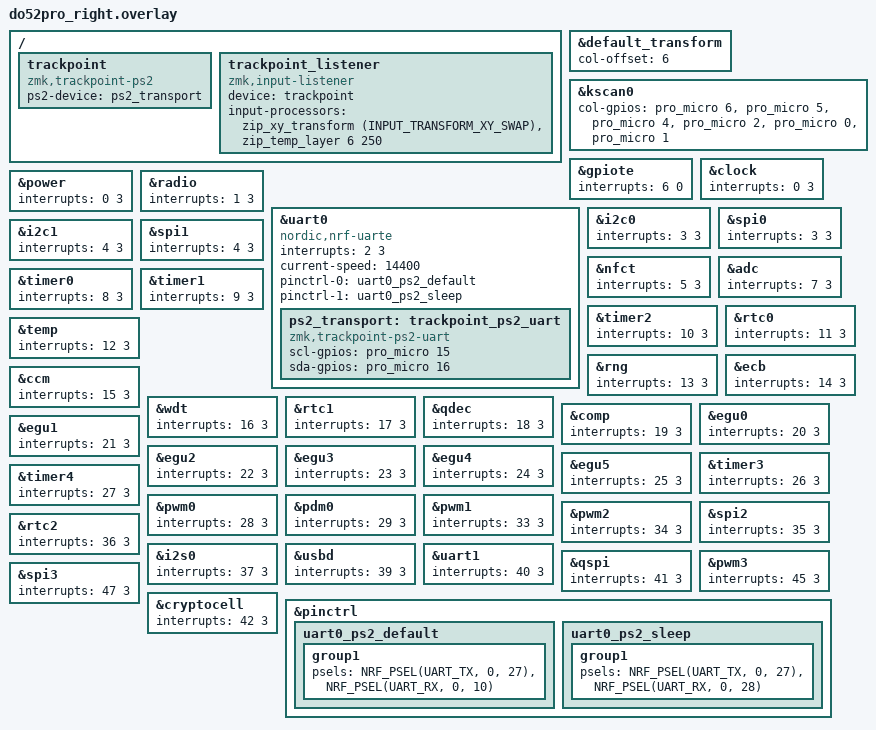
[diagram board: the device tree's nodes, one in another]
#include "do52pro.dtsi"

#include <input/processors.dtsi>
#include <dt-bindings/zmk/input_transform.h>

&default_transform {
    col-offset = <6>;
};

&kscan0 {
    col-gpios
        = <&pro_micro 6 GPIO_ACTIVE_HIGH>
        , <&pro_micro 5 GPIO_ACTIVE_HIGH>
        , <&pro_micro 4 GPIO_ACTIVE_HIGH>
        , <&pro_micro 2 GPIO_ACTIVE_HIGH>
        , <&pro_micro 0 GPIO_ACTIVE_HIGH>
        , <&pro_micro 1 GPIO_ACTIVE_HIGH>
        ;
};

// PS/2 TrackPoint via UART transport
// Pins: SCL=D15 (P1.13), SDA=D16 (P0.10)

// Interrupt priority overrides: the PS/2 clock runs at 10-16.7kHz, so its
// GPIO interrupt must preempt everything, including the BLE radio.
&gpiote { interrupts = < 6 0 >; };
&clock { interrupts = < 0 3 >; };
&power { interrupts = < 0 3 >; };
&radio { interrupts = < 1 3 >; };
&uart0 { interrupts = < 2 3 >; };
&i2c0 { interrupts = < 3 3 >; };
&spi0 { interrupts = < 3 3 >; };
&i2c1 { interrupts = < 4 3 >; };
&spi1 { interrupts = < 4 3 >; };
&nfct { interrupts = < 5 3 >; };
&adc { interrupts = < 7 3 >; };
&timer0 { interrupts = < 8 3 >; };
&timer1 { interrupts = < 9 3 >; };
&timer2 { interrupts = < 10 3 >; };
&rtc0 { interrupts = < 11 3 >; };
&temp { interrupts = < 12 3 >; };
&rng { interrupts = < 13 3 >; };
&ecb { interrupts = < 14 3 >; };
&ccm { interrupts = < 15 3 >; };
&wdt { interrupts = < 16 3 >; };
&rtc1 { interrupts = < 17 3 >; };
&qdec { interrupts = < 18 3 >; };
&comp { interrupts = < 19 3 >; };
&egu0 { interrupts = < 20 3 >; };
&egu1 { interrupts = < 21 3 >; };
&egu2 { interrupts = < 22 3 >; };
&egu3 { interrupts = < 23 3 >; };
&egu4 { interrupts = < 24 3 >; };
&egu5 { interrupts = < 25 3 >; };
&timer3 { interrupts = < 26 3 >; };
&timer4 { interrupts = < 27 3 >; };
&pwm0 { interrupts = < 28 3 >; };
&pdm0 { interrupts = < 29 3 >; };
&pwm1 { interrupts = < 33 3 >; };
&pwm2 { interrupts = < 34 3 >; };
&spi2 { interrupts = < 35 3 >; };
&rtc2 { interrupts = < 36 3 >; };
&i2s0 { interrupts = < 37 3 >; };
&usbd { interrupts = < 39 3 >; };
&uart1 { interrupts = < 40 3 >; };
&qspi { interrupts = < 41 3 >; };
&pwm3 { interrupts = < 45 3 >; };
&spi3 { interrupts = < 47 3 >; };
&cryptocell { interrupts = < 42 3 >; };

// Pinctrl for the PS/2 UART:
// - default: RX on the PS/2 data pin (P0.10), TX parked on unexposed P0.27
// - sleep: both pins parked on unexposed pins, freeing P0.10 for GPIO
//   bit-banging during PS/2 writes
&pinctrl {
    uart0_ps2_default: uart0_ps2_default {
        group1 {
            psels = <NRF_PSEL(UART_TX, 0, 27)>,
                    <NRF_PSEL(UART_RX, 0, 10)>;
        };
    };

    uart0_ps2_sleep: uart0_ps2_sleep {
        group1 {
            psels = <NRF_PSEL(UART_TX, 0, 27)>,
                    <NRF_PSEL(UART_RX, 0, 28)>;
        };
    };
};

&uart0 {
    status = "okay";
    compatible = "nordic,nrf-uarte";

    // 14400 baud matches the ~14.9kHz trackpoint clock
    current-speed = <14400>;
    pinctrl-0 = <&uart0_ps2_default>;
    pinctrl-1 = <&uart0_ps2_sleep>;
    pinctrl-names = "default", "sleep";

    ps2_transport: trackpoint_ps2_uart {
        status = "okay";
        compatible = "zmk,trackpoint-ps2-uart";
        scl-gpios = <&pro_micro 15 GPIO_ACTIVE_HIGH>;
        sda-gpios = <&pro_micro 16 GPIO_ACTIVE_HIGH>;
    };
};

/ {
    trackpoint: trackpoint {
        status = "okay";
        compatible = "zmk,trackpoint-ps2";
        ps2-device = <&ps2_transport>;
    };

    trackpoint_listener: trackpoint_listener {
        compatible = "zmk,input-listener";
        device = <&trackpoint>;

        // Trackpoint is mounted rotated 90deg -> swap axes in software.
        // Moving the trackpoint also momentarily activates the mouse_tp
        // layer (6) for the scroll/click keys.
        input-processors = <&zip_xy_transform (INPUT_TRANSFORM_XY_SWAP)>,
                           <&zip_temp_layer 6 250>;
    };
};
